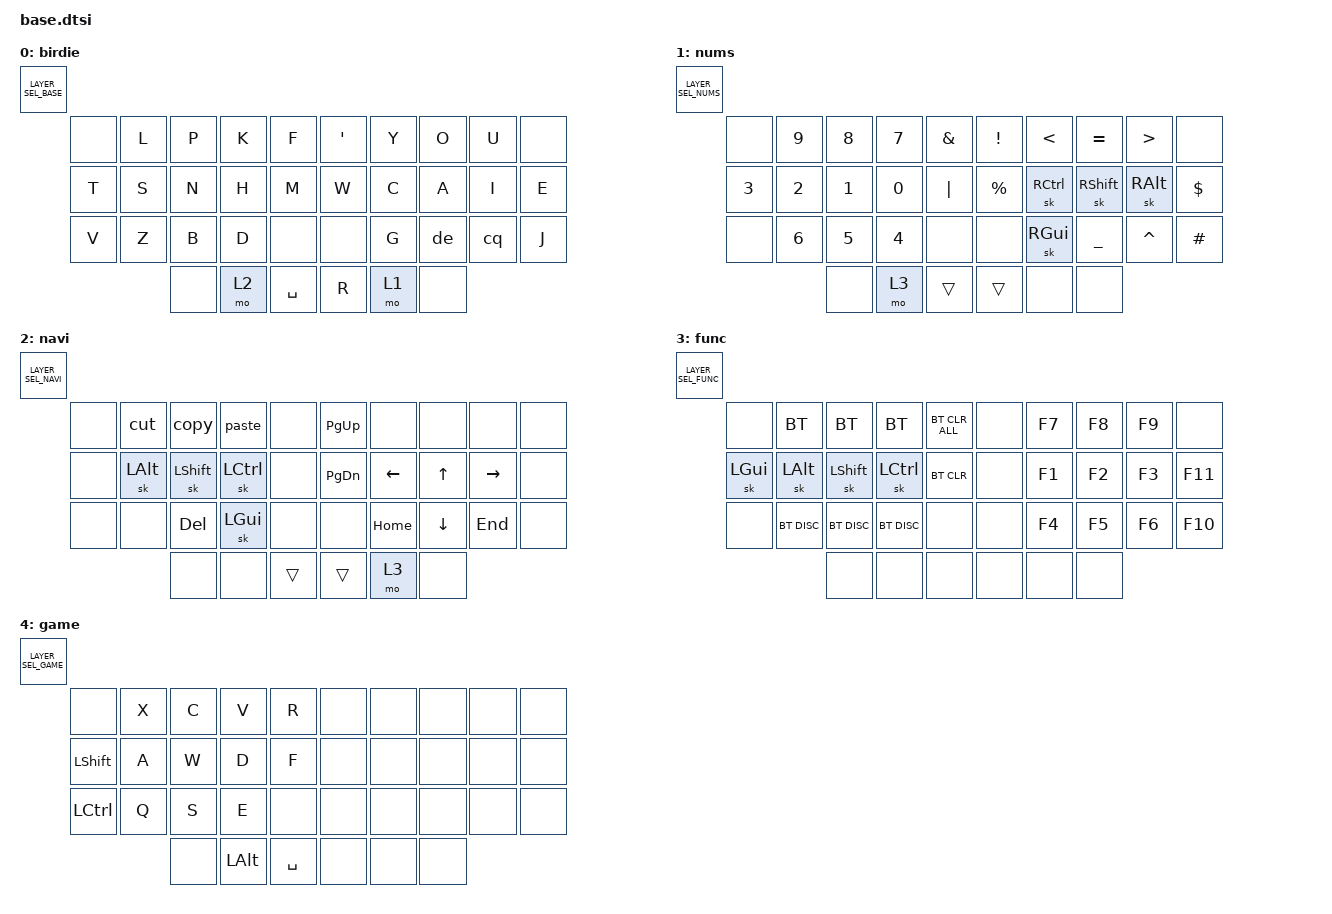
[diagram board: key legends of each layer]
#include <behaviors.dtsi>
#include <dt-bindings/zmk/keys.h>
#include <dt-bindings/zmk/bt.h>

#define BTSL &bt BT_SEL
#define BTDS &bt BT_DISC
#define BTCL &bt BT_CLR
#define BTCA &bt BT_CLR_ALL

#define BASE 0
#define NUMS 1
#define NAVI 2
#define FUNC 3
#define GAME 4

// copy-pasting these blocks for new layers isn't elegant
// TODO: figure out, if possible, how to define one macro for any arbitrary layer?
#ifdef LAYER_BASE
#define LAYER_SEL_BASE LAYER_BASE
#else
#define LAYER_SEL_BASE LAYER
#endif

#ifdef LAYER_NUMS
#define LAYER_SEL_NUMS LAYER_NUMS
#else
#define LAYER_SEL_NUMS LAYER
#endif

#ifdef LAYER_NAVI
#define LAYER_SEL_NAVI LAYER_NAVI
#else
#define LAYER_SEL_NAVI LAYER
#endif

#ifdef LAYER_FUNC
#define LAYER_SEL_FUNC LAYER_FUNC
#else
#define LAYER_SEL_FUNC LAYER
#endif

#ifdef LAYER_GAME
#define LAYER_SEL_GAME LAYER_GAME
#else
#define LAYER_SEL_GAME LAYER
#endif

#include "combos.dtsi"

&sk {
    release-after-ms = <500>;
    quick-release;
};

&caps_word {
    continue-list = <UNDERSCORE MINUS BACKSPACE N0 N1 N2 N3 N4 N5 N6 N7 N8 N9>;
};

// TODO: figure out how to define arbitrary behaviours, layers, and combos per board in keyboard header files
/ {
    macros {
        cut: control_x {
            compatible = "zmk,behavior-macro";
            #binding-cells = <0>;
            bindings = <&macro_press &kp LCTRL>, <&macro_tap &kp X>, <&macro_release &kp LCTRL>;
        };
        copy: control_c {
            compatible = "zmk,behavior-macro";
            #binding-cells = <0>;
            bindings = <&macro_press &kp LCTRL>, <&macro_tap &kp C>, <&macro_release &kp LCTRL>;
        };

        paste: control_v {
            compatible = "zmk,behavior-macro";
            #binding-cells = <0>;
            bindings = <&macro_press &kp LCTRL>, <&macro_tap &kp V>, <&macro_release &kp LCTRL>;
        };
    };

    behaviors {
        de: dot_excl {
            compatible = "zmk,behavior-mod-morph";
            #binding-cells = <0>;
            bindings = <&kp DOT>, <&kp EXCL>;
            mods = <(MOD_LSFT|MOD_RSFT)>;
        };

        cq: comma_qmark {
            compatible = "zmk,behavior-mod-morph";
            #binding-cells = <0>;
            bindings = <&kp COMMA>, <&kp QMARK>;
            mods = <(MOD_LSFT|MOD_RSFT)>;
        };
    };

    keymap {
        compatible = "zmk,keymap";

        zero {
            display-name = "birdie";

            bindings = <LAYER_SEL_BASE( \
                &none,      &kp L,      &kp P,      &kp K,      &kp F,        &kp SQT,    &kp Y,      &kp O,      &kp U,      &none, \
                &kp T,      &kp S,      &kp N,      &kp H,      &kp M,        &kp W,      &kp C,      &kp A,      &kp I,      &kp E, \
                &kp V,      &kp Z,      &kp B,      &kp D,      &none,        &none,      &kp G,      &de,        &cq,        &kp J, \
                                        &none,      &mo 2,      &kp SPACE,    &kp R,      &mo 1,      &none
            )>;
        };

        one {
            display-name = "nums";

            bindings = <LAYER_SEL_NUMS( \
                &none,      &kp N9,     &kp N8,     &kp N7,     &kp AMPS,     &kp EXCL,   &kp LT,     &kp EQUAL,  &kp GT,     &none, \
                &kp N3,     &kp N2,     &kp N1,     &kp N0,     &kp PIPE,     &kp PRCNT,  &sk RCTRL,  &sk RSHFT,  &sk RALT,   &kp DLLR, \
                &none,      &kp N6,     &kp N5,     &kp N4,     &none,        &none,      &sk RGUI,   &kp UNDER,  &kp CARET,  &kp HASH, \
                                        &none,      &mo 3,      &trans,       &trans,     &none,      &none
            )>;
        };

        two {
            display-name = "navi";

            bindings = <LAYER_SEL_NAVI( \
                &none,      &cut,       &copy,      &paste,     &none,       &kp PG_UP,  &none,      &none,      &none,      &none, \
                &none,      &sk LALT,   &sk LSHFT,  &sk LCTRL,  &none,        &kp PG_DN,  &kp LEFT,   &kp UP,     &kp RIGHT,  &none, \
                &none,      &none,      &kp DEL,    &sk LGUI,   &none,        &none,      &kp HOME,   &kp DOWN,   &kp END,    &none, \
                                        &none,      &none,      &trans,       &trans,     &mo 3,      &none
            )>;
        };

        three {
            display-name = "func";

            bindings = <LAYER_SEL_FUNC( \
                &none,      BTSL 3,     BTSL 2,     BTSL 1,     BTCA,         &none,      &kp F7,     &kp F8,     &kp F9,     &none, \
                &sk LGUI,   &sk LALT,   &sk LSHFT,  &sk LCTRL,  BTCL,         &none,      &kp F1,     &kp F2,     &kp F3,     &kp F11, \
                &none,      BTDS 3,     BTDS 2,     BTDS 1,     &none,        &none,      &kp F4,     &kp F5,     &kp F6,     &kp F10, \
                                        &none,      &none,      &none,        &none,      &none,      &none
            )>;
        };

// TODO: find location for 3, perhaps tap-hold x-v for 1-3? also missing g,t,m,y in order of importance
        four {
            display-name = "game";

            bindings = <LAYER_SEL_GAME( \
                &none,      &kp X,      &kp C,      &kp V,      &kp R,        &none,      &none,      &none,      &none,      &none, \
                &kp LSHFT,  &kp A,      &kp W,      &kp D,      &kp F,        &none,      &none,      &none,      &none,      &none, \
                &kp LCTRL,  &kp Q,      &kp S,      &kp E,      &none,        &none,      &none,      &none,      &none,      &none, \
                                        &none,      &kp LALT,   &kp SPACE,    &none,      &none,      &none
            )>;
            
        };
    };
};
